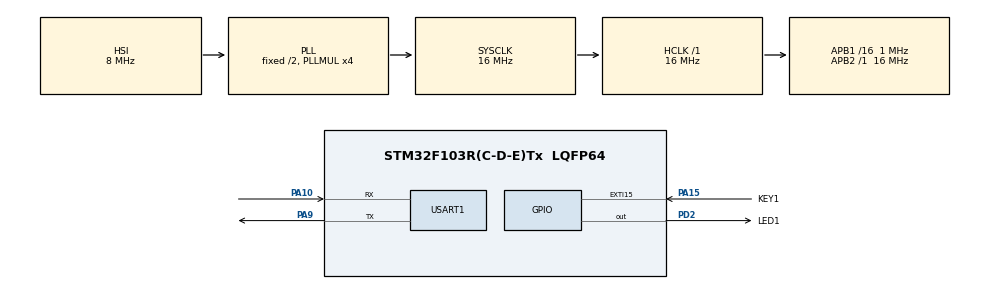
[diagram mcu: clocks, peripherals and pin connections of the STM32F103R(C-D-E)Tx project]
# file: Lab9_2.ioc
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Mcu.Family=STM32F1
Mcu.Name=STM32F103R(C-D-E)Tx
Mcu.Package=LQFP64
NVIC.EXTI15_10_IRQn=true\:1\:0\:true\:false\:true\:true\:true\:true
NVIC.PriorityGroup=NVIC_PRIORITYGROUP_2
NVIC.TIM3_IRQn=true\:1\:0\:true\:false\:true\:true\:true\:true
NVIC.WWDG_IRQn=true\:0\:0\:false\:false\:true\:true\:true\:true
PA10.Mode=Asynchronous
PA10.Signal=USART1_RX
PA15.GPIO_Label=KEY1
PA15.GPIO_ModeDefaultEXTI=GPIO_MODE_IT_FALLING
PA15.GPIO_PuPd=GPIO_PULLUP
PA15.Signal=GPXTI15
PA9.Mode=Asynchronous
PA9.Signal=USART1_TX
PD0-OSC_IN.Mode=HSE-External-Oscillator
PD0-OSC_IN.Signal=RCC_OSC_IN
PD1-OSC_OUT.Mode=HSE-External-Oscillator
PD1-OSC_OUT.Signal=RCC_OSC_OUT
PD2.GPIO_Label=LED1
PD2.PinState=GPIO_PIN_SET
PD2.Signal=GPIO_Output
ProjectManager.HeapSize=0x200
ProjectManager.StackSize=0x400
ProjectManager.TargetToolchain=STM32CubeIDE
RCC.AHBFreq_Value=16000000
RCC.APB1CLKDivider=RCC_HCLK_DIV16
RCC.APB1Freq_Value=1000000
RCC.APB1TimFreq_Value=2000000
RCC.APB2Freq_Value=16000000
RCC.APB2TimFreq_Value=16000000
RCC.HCLKFreq_Value=16000000
RCC.PLLMUL=RCC_PLL_MUL4
RCC.SYSCLKFreq_VALUE=16000000
RCC.SYSCLKSource=RCC_SYSCLKSOURCE_PLLCLK
RCC.USBFreq_Value=16000000
TIM3.Period=999
TIM3.Prescaler=159
USART1.VirtualMode=VM_ASYNC
VP_SYS_VS_ND.Mode=No_Debug
VP_TIM3_VS_ClockSourceINT.Mode=Internal
VP_WWDG_VS_WWDG.Mode=WWDG_Activate
WWDG.Counter=127
WWDG.EWIMode=WWDG_EWI_ENABLE
WWDG.Prescaler=WWDG_PRESCALER_8
WWDG.Window=95
board=custom

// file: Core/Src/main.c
/* USER CODE BEGIN Header */
/**
  ******************************************************************************
  * @file           : main.c
  * @brief          : Main program body
  ******************************************************************************
  * @attention
  *
  * Copyright (c) 2024 STMicroelectronics.
  * All rights reserved.
  *
  * This software is licensed under terms that can be found in the LICENSE file
  * in the root directory of this software component.
  * If no LICENSE file comes with this software, it is provided AS-IS.
  *
  ******************************************************************************
  */
/* USER CODE END Header */
#include "main.h"

/* USER CODE BEGIN Includes */
#include <string.h>
#include <stdio.h>

/* USER CODE END Includes */

TIM_HandleTypeDef htim3;

UART_HandleTypeDef huart1;

WWDG_HandleTypeDef hwwdg;

/* USER CODE BEGIN PV */
int i = 0;
/* USER CODE END PV */

void SystemClock_Config(void);
static void MX_GPIO_Init(void);
static void MX_USART1_UART_Init(void);
static void MX_WWDG_Init(void);
static void MX_TIM3_Init(void);

int main(void)
{

  /* MCU Configuration--------------------------------------------------------*/

  /* Reset of all peripherals, Initializes the Flash interface and the Systick. */
  HAL_Init();

  /* Configure the system clock */
  SystemClock_Config();

  /* Initialize all configured peripherals */
  MX_GPIO_Init();
  MX_USART1_UART_Init();
  MX_WWDG_Init();
  MX_TIM3_Init();
  /* USER CODE BEGIN 2 */
  HAL_UART_Transmit(&huart1, "Restart\r\n", 9, HAL_MAX_DELAY);
  __HAL_TIM_CLEAR_IT(&htim3,TIM_IT_UPDATE);
  HAL_TIM_Base_Start_IT(&htim3);
  HAL_GPIO_WritePin(GPIOD, LED1_Pin, SET);
  char msg[100];
  /* USER CODE END 2 */

  /* Infinite loop */
  while (1)
  {

    /* USER CODE BEGIN 3 */
	  if(i == 0){
		  HAL_UART_Transmit(&huart1, "Restart\r\n", 9, HAL_MAX_DELAY);
	  }
	  i++;
	  sprintf(msg, "i = %d\r\n", i);
	  HAL_UART_Transmit(&huart1, (uint8_t*)msg, strlen(msg), HAL_MAX_DELAY);
	  HAL_Delay(1000);
  }
  /* USER CODE END 3 */
}

void SystemClock_Config(void)
{
  RCC_OscInitTypeDef RCC_OscInitStruct = {0};
  RCC_ClkInitTypeDef RCC_ClkInitStruct = {0};

  /** Initializes the RCC Oscillators according to the specified parameters
  * in the RCC_OscInitTypeDef structure.
  */
  RCC_OscInitStruct.OscillatorType = RCC_OSCILLATORTYPE_HSI;
  RCC_OscInitStruct.HSIState = RCC_HSI_ON;
  RCC_OscInitStruct.HSICalibrationValue = RCC_HSICALIBRATION_DEFAULT;
  RCC_OscInitStruct.PLL.PLLState = RCC_PLL_ON;
  RCC_OscInitStruct.PLL.PLLSource = RCC_PLLSOURCE_HSI_DIV2;
  RCC_OscInitStruct.PLL.PLLMUL = RCC_PLL_MUL4;
  if (HAL_RCC_OscConfig(&RCC_OscInitStruct) != HAL_OK)
  {
    Error_Handler();
  }

  /** Initializes the CPU, AHB and APB buses clocks
  */
  RCC_ClkInitStruct.ClockType = RCC_CLOCKTYPE_HCLK|RCC_CLOCKTYPE_SYSCLK
                              |RCC_CLOCKTYPE_PCLK1|RCC_CLOCKTYPE_PCLK2;
  RCC_ClkInitStruct.SYSCLKSource = RCC_SYSCLKSOURCE_PLLCLK;
  RCC_ClkInitStruct.AHBCLKDivider = RCC_SYSCLK_DIV1;
  RCC_ClkInitStruct.APB1CLKDivider = RCC_HCLK_DIV16;
  RCC_ClkInitStruct.APB2CLKDivider = RCC_HCLK_DIV1;

  if (HAL_RCC_ClockConfig(&RCC_ClkInitStruct, FLASH_LATENCY_0) != HAL_OK)
  {
    Error_Handler();
  }
}

static void MX_TIM3_Init(void)
{

  TIM_ClockConfigTypeDef sClockSourceConfig = {0};
  TIM_MasterConfigTypeDef sMasterConfig = {0};

  htim3.Instance = TIM3;
  htim3.Init.Prescaler = 159;
  htim3.Init.CounterMode = TIM_COUNTERMODE_UP;
  htim3.Init.Period = 999;
  htim3.Init.ClockDivision = TIM_CLOCKDIVISION_DIV1;
  htim3.Init.AutoReloadPreload = TIM_AUTORELOAD_PRELOAD_DISABLE;
  if (HAL_TIM_Base_Init(&htim3) != HAL_OK)
  {
    Error_Handler();
  }
  sClockSourceConfig.ClockSource = TIM_CLOCKSOURCE_INTERNAL;
  if (HAL_TIM_ConfigClockSource(&htim3, &sClockSourceConfig) != HAL_OK)
  {
    Error_Handler();
  }
  sMasterConfig.MasterOutputTrigger = TIM_TRGO_RESET;
  sMasterConfig.MasterSlaveMode = TIM_MASTERSLAVEMODE_DISABLE;
  if (HAL_TIMEx_MasterConfigSynchronization(&htim3, &sMasterConfig) != HAL_OK)
  {
    Error_Handler();
  }

}

static void MX_USART1_UART_Init(void)
{

  huart1.Instance = USART1;
  huart1.Init.BaudRate = 115200;
  huart1.Init.WordLength = UART_WORDLENGTH_8B;
  huart1.Init.StopBits = UART_STOPBITS_1;
  huart1.Init.Parity = UART_PARITY_NONE;
  huart1.Init.Mode = UART_MODE_TX_RX;
  huart1.Init.HwFlowCtl = UART_HWCONTROL_NONE;
  huart1.Init.OverSampling = UART_OVERSAMPLING_16;
  if (HAL_UART_Init(&huart1) != HAL_OK)
  {
    Error_Handler();
  }

}

static void MX_WWDG_Init(void)
{

  hwwdg.Instance = WWDG;
  hwwdg.Init.Prescaler = WWDG_PRESCALER_8;
  hwwdg.Init.Window = 95;
  hwwdg.Init.Counter = 127;
  hwwdg.Init.EWIMode = WWDG_EWI_ENABLE;
  if (HAL_WWDG_Init(&hwwdg) != HAL_OK)
  {
    Error_Handler();
  }

}

static void MX_GPIO_Init(void)
{
  GPIO_InitTypeDef GPIO_InitStruct = {0};

  /* GPIO Ports Clock Enable */
  __HAL_RCC_GPIOD_CLK_ENABLE();
  __HAL_RCC_GPIOA_CLK_ENABLE();

  /*Configure GPIO pin Output Level */
  HAL_GPIO_WritePin(LED1_GPIO_Port, LED1_Pin, GPIO_PIN_SET);

  /*Configure GPIO pin : KEY1_Pin */
  GPIO_InitStruct.Pin = KEY1_Pin;
  GPIO_InitStruct.Mode = GPIO_MODE_IT_FALLING;
  GPIO_InitStruct.Pull = GPIO_PULLUP;
  HAL_GPIO_Init(KEY1_GPIO_Port, &GPIO_InitStruct);

  /*Configure GPIO pin : LED1_Pin */
  GPIO_InitStruct.Pin = LED1_Pin;
  GPIO_InitStruct.Mode = GPIO_MODE_OUTPUT_PP;
  GPIO_InitStruct.Pull = GPIO_NOPULL;
  GPIO_InitStruct.Speed = GPIO_SPEED_FREQ_LOW;
  HAL_GPIO_Init(LED1_GPIO_Port, &GPIO_InitStruct);

  /* EXTI interrupt init*/
  HAL_NVIC_SetPriority(EXTI15_10_IRQn, 1, 0);
  HAL_NVIC_EnableIRQ(EXTI15_10_IRQn);

}

void Error_Handler(void)
{
  __disable_irq();
  while (1)
  {
  }
}
